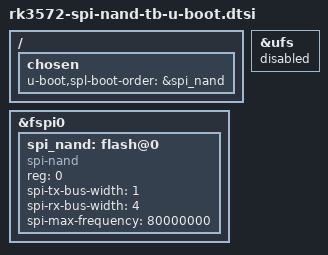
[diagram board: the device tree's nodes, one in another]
// SPDX-License-Identifier: (GPL-2.0+ OR MIT)
/*
 * Copyright (c) 2026 Rockchip Electronics Co., Ltd.
 */

#include "rk3572-tb-u-boot.dtsi"

/ {
	chosen {
		u-boot,spl-boot-order = &spi_nand;
	};
};

&fspi0 {
	bootph-all;
	status = "okay";

	#address-cells = <1>;
	#size-cells = <0>;
	spi_nand: flash@0 {
		bootph-all;
		compatible = "spi-nand";
		reg = <0>;
		spi-tx-bus-width = <1>;
		spi-rx-bus-width = <4>;
		spi-max-frequency = <80000000>;
	};
};

&ufs {
	/delete-property/ bootph-all;
	status = "disabled";
};
